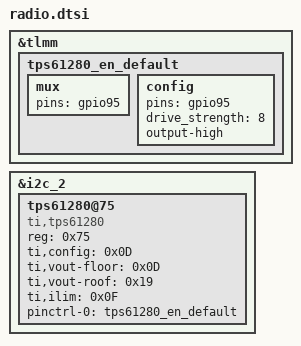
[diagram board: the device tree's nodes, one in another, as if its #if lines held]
#ifdef DEVICE_JETER
&tlmm{
	tps61280_en_default: tps61280_en_default {
		mux {
			pins = "gpio95";
		};
		config {
			pins = "gpio95";
			drive_strength = <8>;
			output-high;
		};
	};
};

&i2c_2 {
	tps61280@75 {
		compatible = "ti,tps61280";
		status = "okay";
		reg = <0x75>;
		ti,config = <0x0D>;
		ti,vout-floor = <0x0D>;
		ti,vout-roof = <0x19>;
		ti,ilim = <0x0F>;
		pinctrl-names = "default";
		pinctrl-0 = <&tps61280_en_default>;
	};
};
#endif
